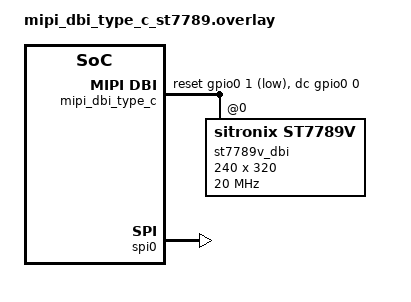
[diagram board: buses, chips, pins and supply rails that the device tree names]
/*
 * Copyright 2026 Alp Lab AB
 * SPDX-License-Identifier: Apache-2.0
 *
 * Build-only MIPI DBI Type C fixture for the alp-sdk display ztest.
 *
 * This instantiates Zephyr's upstream "zephyr,mipi-dbi-spi" controller
 * and a Sitronix ST7789V child panel on native_sim's emulated SPI/GPIO
 * buses.  The panel is exposed as both zephyr,display and alp-display0,
 * matching the nodes customer boards provide for LVGL and <alp/display.h>.
 *
 * native_sim's SPI controller needs a target emulator for real transfers,
 * so this fixture is intentionally build-only: it proves the Kconfig,
 * devicetree, and display backend wiring without pretending to validate
 * panel IO.
 */

#include <zephyr/dt-bindings/gpio/gpio.h>
#include <zephyr/dt-bindings/mipi_dbi/mipi_dbi.h>

/ {
	chosen {
		zephyr,display = &st7789v_dbi;
	};

	aliases {
		alp-display0 = &st7789v_dbi;
	};

	mipi_dbi_type_c {
		compatible = "zephyr,mipi-dbi-spi";
		spi-dev = <&spi0>;
		dc-gpios = <&gpio0 0 GPIO_ACTIVE_HIGH>;
		reset-gpios = <&gpio0 1 GPIO_ACTIVE_LOW>;
		write-only;
		#address-cells = <1>;
		#size-cells = <0>;

		st7789v_dbi: st7789v@0 {
			compatible = "sitronix,st7789v";
			reg = <0>;
			mipi-max-frequency = <20000000>;
			width = <240>;
			height = <320>;
			x-offset = <0>;
			y-offset = <0>;
			vcom = <0x19>;
			gctrl = <0x35>;
			vrhs = <0x12>;
			vdvs = <0x20>;
			mdac = <0x00>;
			gamma = <0x01>;
			colmod = <0x05>;
			lcm = <0x2c>;
			porch-param = [0c 0c 00 33 33];
			cmd2en-param = [5a 69 02 01];
			pwctrl1-param = [a4 a1];
			pvgam-param = [d0 04 0d 11 13 2b 3f 54 4c 18 0d 0b 1f 23];
			nvgam-param = [d0 04 0c 11 13 2c 3f 44 51 2f 1f 1f 20 23];
			ram-param = [00 f0];
			rgb-param = [cd 08 14];
			mipi-mode = "MIPI_DBI_MODE_SPI_4WIRE";
		};
	};
};

&spi0 {
	status = "okay";
	cs-gpios = <&gpio0 2 GPIO_ACTIVE_LOW>;
};

&gpio0 {
	status = "okay";
};
